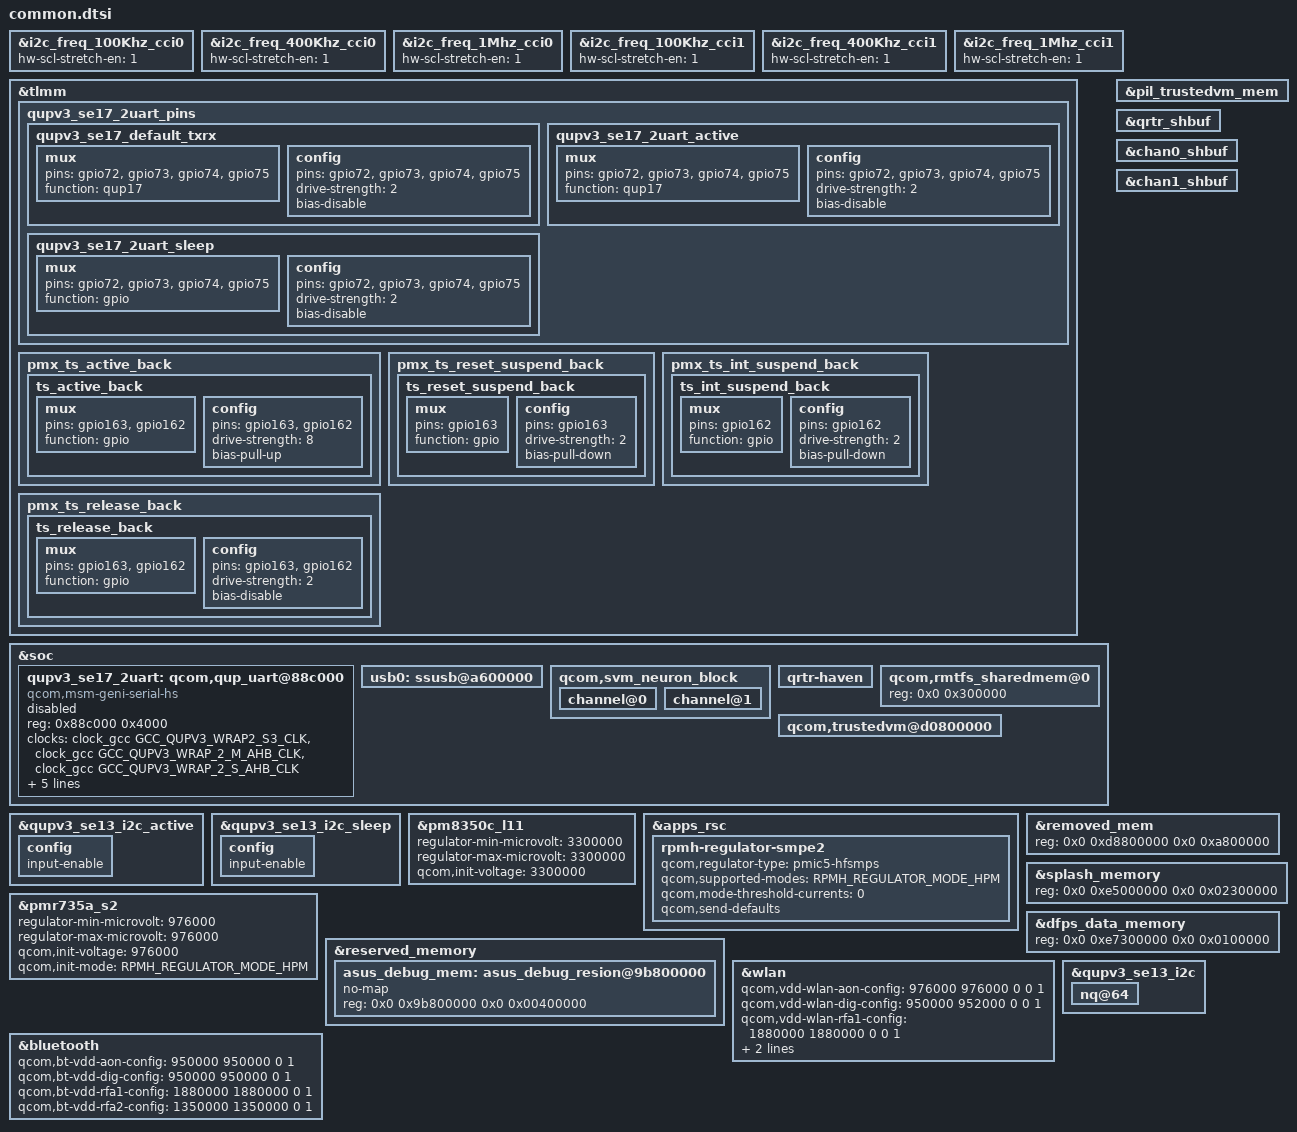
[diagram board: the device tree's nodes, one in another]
/*
 * Common qcom dtsi changes for Sake and Vodka platforms
 */

&i2c_freq_100Khz_cci0 {
	hw-scl-stretch-en = <1>;
};

&i2c_freq_400Khz_cci0 {
	hw-scl-stretch-en = <1>;
};

&i2c_freq_1Mhz_cci0 {
	hw-scl-stretch-en = <1>;
};

&i2c_freq_100Khz_cci1 {
	hw-scl-stretch-en = <1>;
};

&i2c_freq_400Khz_cci1 {
	hw-scl-stretch-en = <1>;
};

&i2c_freq_1Mhz_cci1 {
	hw-scl-stretch-en = <1>;
};

&tlmm {
	qupv3_se17_2uart_pins: qupv3_se17_2uart_pins {
		qupv3_se17_default_txrx: qupv3_se17_default_txrx {
			mux {
				pins = "gpio72", "gpio73",
						"gpio74", "gpio75";
				function = "qup17";
			};

			config {
				pins = "gpio72", "gpio73",
						"gpio74", "gpio75";
				drive-strength = <2>;
				bias-disable;
			};
		};

		qupv3_se17_2uart_active: qupv3_se17_2uart_active {
			mux {
				pins = "gpio72", "gpio73",
						"gpio74", "gpio75";
				function = "qup17";
			};

			config {
				pins = "gpio72", "gpio73",
						"gpio74", "gpio75";
				drive-strength = <2>;
				bias-disable;
			};
		};

		qupv3_se17_2uart_sleep: qupv3_se17_2uart_sleep {
			mux {
				pins = "gpio72", "gpio73",
						"gpio74", "gpio75";
				function = "gpio";
			};

			config {
				pins = "gpio72", "gpio73",
						"gpio74", "gpio75";
				drive-strength = <2>;
				bias-disable;
			};
		};
	};

	pmx_ts_active_back {
		ts_active_back: ts_active_back {
			mux {
				pins = "gpio163", "gpio162";
				function = "gpio";
			};

			config {
				pins = "gpio163", "gpio162";
				drive-strength = <8>;
				bias-pull-up;
			};
		};
	};

	pmx_ts_reset_suspend_back {
		ts_reset_suspend_back: ts_reset_suspend_back {
			mux {
				pins = "gpio163";
				function = "gpio";
			};

			config {
				pins = "gpio163";
				drive-strength = <2>;
				bias-pull-down;
			};
		};
	};

	pmx_ts_int_suspend_back {
		ts_int_suspend_back: ts_int_suspend_back {
			mux {
				pins = "gpio162";
				function = "gpio";
			};

			config {
				pins = "gpio162";
				drive-strength = <2>;
				bias-pull-down;
			};
		};
	};

	pmx_ts_release_back {
		ts_release_back: ts_release_back {
			mux {
				pins = "gpio163", "gpio162";
				function = "gpio";
			};

			config {
				pins = "gpio163", "gpio162";
				drive-strength = <2>;
				bias-disable;
			};
		};
	};
};

&soc {
	qupv3_se17_2uart: qcom,qup_uart@88c000 {
	    compatible = "qcom,msm-geni-serial-hs";
	    reg = <0x88c000 0x4000>;
	    reg-names = "se_phys";
	    clock-names = "se-clk", "m-ahb", "s-ahb";
	    clocks = <&clock_gcc GCC_QUPV3_WRAP2_S3_CLK>,
		<&clock_gcc GCC_QUPV3_WRAP_2_M_AHB_CLK>,
		<&clock_gcc GCC_QUPV3_WRAP_2_S_AHB_CLK>;
	    pinctrl-names = "default", "active", "sleep";
	    pinctrl-0 = <&qupv3_se17_default_txrx>;
	    pinctrl-1 = <&qupv3_se17_2uart_active>;
	    pinctrl-2 = <&qupv3_se17_2uart_sleep>;
	    interrupts = <GIC_SPI 585 IRQ_TYPE_LEVEL_HIGH>;
	    qcom,wrapper-core = <&qupv3_2>;
	    status = "disabled";
	};

	usb0: ssusb@a600000 {
		/delete-property/ extcon;
	};

	qcom,svm_neuron_block {
		channel@0 {
			/delete-property/ shared-buffer;
		};

		channel@1 {
			/delete-property/ shared-buffer;
		};
	};

	qrtr-haven {
		/delete-property/ shared-buffer;
	};

	qcom,rmtfs_sharedmem@0 {
		reg = <0x0 0x300000>;
	};

	qcom,trustedvm@d0800000 {
		/delete-property/ memory-region;
	};
};

&qupv3_se13_i2c_active {
	config {
		input-enable;
	};
};

&qupv3_se13_i2c_sleep {
	config {
		input-enable;
	};
};

&pm8350c_l11 {
	regulator-min-microvolt = <3300000>;
	regulator-max-microvolt = <3300000>;
	qcom,init-voltage = <3300000>;
};

&apps_rsc {
	rpmh-regulator-smpe2 {
		qcom,regulator-type = "pmic5-hfsmps";
		qcom,supported-modes = <RPMH_REGULATOR_MODE_HPM>;
		qcom,mode-threshold-currents = <0>;
		qcom,send-defaults;
	};
};

&pmr735a_s2 {
	regulator-min-microvolt = <976000>;
	regulator-max-microvolt = <976000>;
	qcom,init-voltage = <976000>;
	qcom,init-mode = <RPMH_REGULATOR_MODE_HPM>;
};

&reserved_memory {
	asus_debug_mem: asus_debug_resion@9b800000 {
		no-map;
		reg = <0x0 0x9b800000 0x0 0x00400000>;
	};
};

&pil_trustedvm_mem {
	/delete-property/ reg;
};

&qrtr_shbuf {
	/delete-property/ reg;
};

&chan0_shbuf {
	/delete-property/ reg;
};

&chan1_shbuf {
	/delete-property/ reg;
};

&removed_mem {
	reg = <0x0 0xd8800000 0x0 0xa800000>;
};

&splash_memory {
	reg = <0x0 0xe5000000 0x0 0x02300000>;
};

&dfps_data_memory {
	reg = <0x0 0xe7300000 0x0 0x0100000>;
};

&wlan {
	qcom,vdd-wlan-aon-config = <976000 976000 0 0 1>;
	qcom,vdd-wlan-dig-config = <950000 952000 0 0 1>;
	qcom,vdd-wlan-rfa1-config = <1880000 1880000 0 0 1>;
	qcom,vdd-wlan-rfa2-config = <1350000 1350000 0 0 1>;
};

&bluetooth {
	qcom,bt-vdd-aon-config = <950000 950000 0 1>;
	qcom,bt-vdd-dig-config = <950000 950000 0 1>;
	qcom,bt-vdd-rfa1-config = <1880000 1880000 0 1>;
	qcom,bt-vdd-rfa2-config = <1350000 1350000 0 1>;
};

&qupv3_se13_i2c {
	nq@64 {
		/delete-property/ vdd-supply;
		/delete-property/ rtc6226,vdd-supply-voltage;
	};
};
